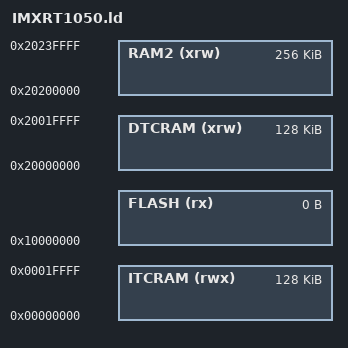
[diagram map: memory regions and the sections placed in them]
MEMORY
{
  FLASH (rx) :    ORIGIN = 0x10000000, LENGTH = 0K

  ITCRAM (rwx) :  ORIGIN = 0x00000000, LENGTH = 128K
  DTCRAM (xrw) :  ORIGIN = 0x20000000, LENGTH = 128K
  RAM2 (xrw) :    ORIGIN = 0x20200000, LENGTH = 256K
}

REGION_ALIAS("RAM", DTCRAM);
REGION_ALIAS("TEXT", ITCRAM);

INCLUDE nvcm_default_noflash.ld

